# PIC32CM5164LS00048 register map
Vendor: Microchip Technology; Series: PIC32CMLS00; File version: 0
CPU: CM23 r0p0, selectable endian, MPU, no FPU, 2 interrupt priority bits
Registers are 32-bit, read-write, reset 0x0 unless marked. A register's access mark holds for its fields unless they carry their own. Offsets are from the block's base; [hi:lo] are bit positions; 'fields as' and 'values as' point back to an identical list.

## PTC — Peripheral Touch Controller
Base 0x42004000; register names take the prefix PTC_

## RSTC — Reset Controller
Base 0x40000C00; register names take the prefix RSTC_
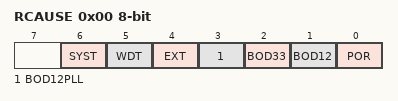
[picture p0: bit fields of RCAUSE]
0x00 RCAUSE 8-bit ro — Reset Cause
  [6] SYST — System Reset Request
  [5] WDT — Watchdog Reset
  [4] EXT — External Reset
  [3] BOD12PLL — Brown Out VDDPLL Detector Reset
  [2] BOD33 — Brown Out VDD/AVDD Detector Reset
  [1] BOD12 — Brown Out VDDCORE Detector Reset
  [0] POR — Power On Reset

## SUPC — Supply Controller
Base 0x40001800; register names take the prefix SUPC_
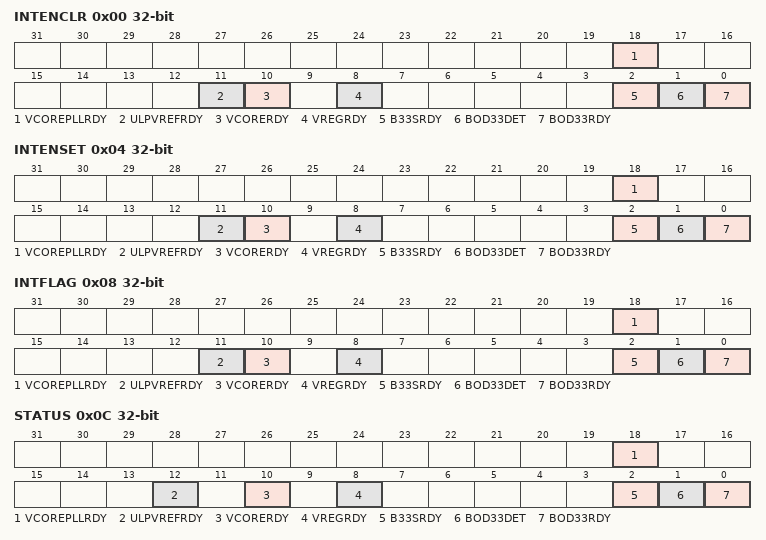
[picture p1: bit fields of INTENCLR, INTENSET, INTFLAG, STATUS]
0x00 INTENCLR — Interrupt Enable Clear
  [18] VCOREPLLRDY — Voltage Regulator PLL Ready
  [11] ULPVREFRDY — ULPVREF Voltage Reference Ready
  [10] VCORERDY — VDDCORE Ready
  [8] VREGRDY — Voltage Regulator Ready
  [2] B33SRDY — BOD33 Synchronization Ready
  [1] BOD33DET — BOD33 Detection
  [0] BOD33RDY — BOD33 Ready
0x04 INTENSET — Interrupt Enable Set
  fields as INTENCLR
0x08 INTFLAG — Interrupt Flag Status and Clear
  fields as INTENCLR
0x0C STATUS ro — Power and Clocks Status
  [18] VCOREPLLRDY — Voltage Regulator PLL Ready
  [12] ULPVREFRDY — Low Power Voltage Reference Ready
  [10] VCORERDY — VDDCORE Ready
  [8] VREGRDY — Voltage Regulator Ready
  [2] B33SRDY — BOD33 Synchronization Ready
  [1] BOD33DET — BOD33 Detection
  [0] BOD33RDY — BOD33 Ready
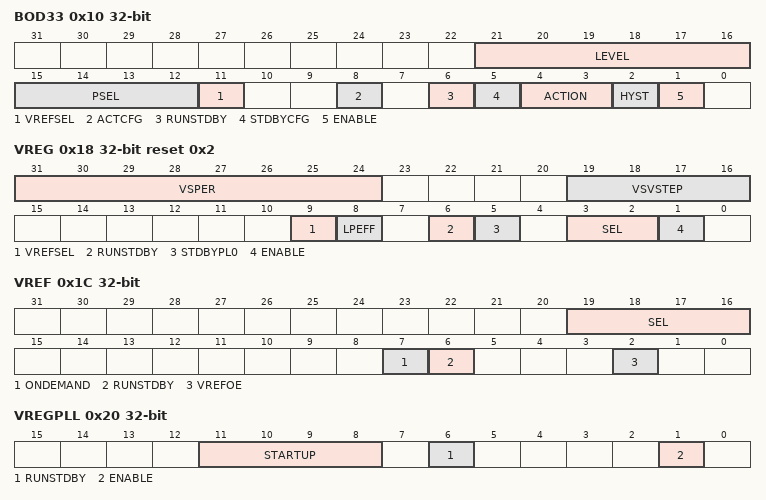
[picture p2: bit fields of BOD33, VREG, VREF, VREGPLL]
0x10 BOD33 — BOD33 Control
  [21:16] LEVEL — Threshold Level for VDD/AVDD
  [15:12] PSEL — Prescaler Select
    0=DIV2 (Divide clock by 2); 1=DIV4 (Divide clock by 4); 2=DIV8 (Divide clock by 8); 3=DIV16 (Divide clock by 16); 4=DIV32 (Divide clock by 32); 5=DIV64 (Divide clock by 64); 6=DIV128 (Divide clock by 128); 7=DIV256 (Divide clock by 256); 8=DIV512 (Divide clock by 512); 9=DIV1024 (Divide clock by 1024); 10=DIV2048 (Divide clock by 2048); 11=DIV4096 (Divide clock by 4096); 12=DIV8192 (Divide clock by 8192); 13=DIV16384 (Divide clock by 16384); 14=DIV32768 (Divide clock by 32768); 15=DIV65536 (Divide clock by 65536)
  [11] VREFSEL — BOD33 Voltage Reference Selection
    0=SEL_VREF (Selects VREF for the BOD33); 1=SEL_ULPVREF (Selects ULPVREF for the BOD33)
  [8] ACTCFG — Configuration in Active mode
  [6] RUNSTDBY — Run during Standby
  [5] STDBYCFG — Configuration in Standby mode
  [4:3] ACTION — Action when Threshold Crossed
    0=NONE (No action); 1=RESET (The BOD33 generates a reset); 2=INT (The BOD33 generates an interrupt)
  [2] HYST — Hysteresis Enable
  [1] ENABLE
0x18 VREG reset 0x2 — VREG Control
  [31:24] VSPER — Voltage Scaling Period
  [19:16] VSVSTEP — Voltage Scaling Voltage Step
  [9] VREFSEL — Voltage Regulator Voltage Reference Selection
    0=SEL_VREF (Selects VREF for the VREG); 1=SEL_ULPVREF (Selects ULPVREF for the VREG)
  [8] LPEFF — Low Power efficiency
  [6] RUNSTDBY — Run during Standby
  [5] STDBYPL0 — Standby in PL0
  [3:2] SEL — Voltage Regulator Selection in active mode
    0=LDO (LDO selection); 1=BUCK (Buck selection)
  [1] ENABLE
0x1C VREF — VREF Control
  [19:16] SEL — Voltage Reference Selection for ADC/DAC
    6=2V4 (2.4V voltage reference typical value); 7=2V5 (2.5V voltage reference typical value)
  [7] ONDEMAND — On Demand Control
  [6] RUNSTDBY — Run during Standby
  [2] VREFOE — Voltage Reference Output Enable
0x20 VREGPLL — VREGPLL Control
  [11:8] STARTUP — Startup Time
  [6] RUNSTDBY — Run during Standby
  [1] ENABLE — Vreg PLL Enable
0x2C EVCTRL — Event Control
  [1] BOD33DETEO — BOD33 Detection Event Output Enable

## SysTick — SysTick Timer
Base 0xE000E010; register names take the prefix SysTick_
Same registers: SysTick_NS 0xE002E010
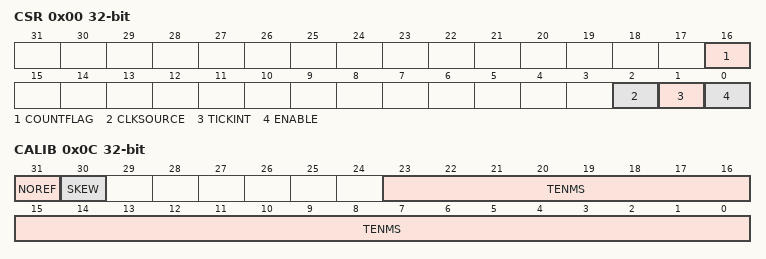
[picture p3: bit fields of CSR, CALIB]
0x00 CSR — SysTick Control and Status Register
  [16] COUNTFLAG
  [2] CLKSOURCE — Clock source
  [1] TICKINT — Tick interrupt
  [0] ENABLE — SysTick enable
0x04 RVR — SysTick Reload Value Register
  [24] RELOAD — Counter reload value
0x08 CVR — SysTick Current Value Register
  [24] CURRENT — Current counter value
0x0C CALIB ro — SysTick Calibration Value Register
  [31] NOREF — No reference
  [30] SKEW
  [23:0] TENMS — Ten milliseconds

## Notices in the file
Copyright (c) 2017 Microchip Technology Inc.
SPDX-License-Identifier: Apache-2.0
Licensed under the Apache License, Version 2.0 (the "License");
you may not use this file except in compliance with the License.
You may obtain a copy of the License at
http://www.apache.org/licenses/LICENSE-2.0
Unless required by applicable law or agreed to in writing, software
distributed under the License is distributed on an "AS IS" BASIS,
WITHOUT WARRANTIES OR CONDITIONS OF ANY KIND, either express or implied.
See the License for the specific language governing permissions and
limitations under the License.
